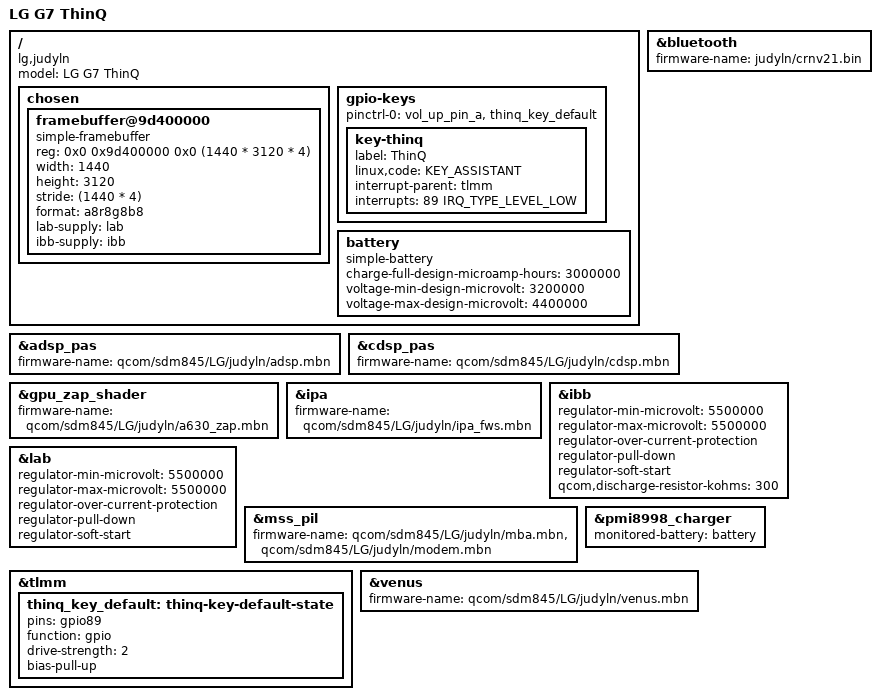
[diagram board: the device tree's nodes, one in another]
// SPDX-License-Identifier: GPL-2.0
/*
 * SDM845 LG G7 (judyln) device tree.
 *
 * Copyright (c) 2022, The Linux Foundation. All rights reserved.
 */

/dts-v1/;

#include "sdm845-lg-common.dtsi"

/ {
	model = "LG G7 ThinQ";
	compatible = "lg,judyln", "qcom,sdm845";

	chosen {
		framebuffer@9d400000 {
			compatible = "simple-framebuffer";
			reg = <0x0 0x9d400000 0x0 (1440 * 3120 * 4)>;
			width = <1440>;
			height = <3120>;
			stride = <(1440 * 4)>;
			format = "a8r8g8b8";
			lab-supply = <&lab>;
			ibb-supply = <&ibb>;
		};
	};

	/* Additional ThinQ key */
	gpio-keys {
		pinctrl-0 = <&vol_up_pin_a &thinq_key_default>;

		key-thinq {
			label = "ThinQ";
			linux,code = <KEY_ASSISTANT>;
			interrupt-parent = <&tlmm>;
			interrupts = <89 IRQ_TYPE_LEVEL_LOW>;
		};
	};

	battery: battery {
		compatible = "simple-battery";

		charge-full-design-microamp-hours = <3000000>;
		voltage-min-design-microvolt = <3200000>;
		voltage-max-design-microvolt = <4400000>;
	};
};

&adsp_pas {
	firmware-name = "qcom/sdm845/LG/judyln/adsp.mbn";
};

&bluetooth {
	/*
	 * This path is relative to the qca/
	 * subdir under lib/firmware.
	 */
	firmware-name = "judyln/crnv21.bin";
};

&cdsp_pas {
	firmware-name = "qcom/sdm845/LG/judyln/cdsp.mbn";
};

&gpu_zap_shader {
	firmware-name = "qcom/sdm845/LG/judyln/a630_zap.mbn";
};

&ipa {
	firmware-name = "qcom/sdm845/LG/judyln/ipa_fws.mbn";
};

&ibb {
	regulator-min-microvolt = <5500000>;
	regulator-max-microvolt = <5500000>;
	regulator-over-current-protection;
	regulator-pull-down;
	regulator-soft-start;
	qcom,discharge-resistor-kohms = <300>;
};

&lab {
	regulator-min-microvolt = <5500000>;
	regulator-max-microvolt = <5500000>;
	regulator-over-current-protection;
	regulator-pull-down;
	regulator-soft-start;
};

&mss_pil {
	firmware-name = "qcom/sdm845/LG/judyln/mba.mbn", "qcom/sdm845/LG/judyln/modem.mbn";
};

&pmi8998_charger {
	monitored-battery = <&battery>;

	status = "okay";
};

&tlmm {
	thinq_key_default: thinq-key-default-state {
		pins = "gpio89";
		function = "gpio";

		drive-strength = <2>;
		bias-pull-up;
	};
};

&venus {
	firmware-name = "qcom/sdm845/LG/judyln/venus.mbn";
};
